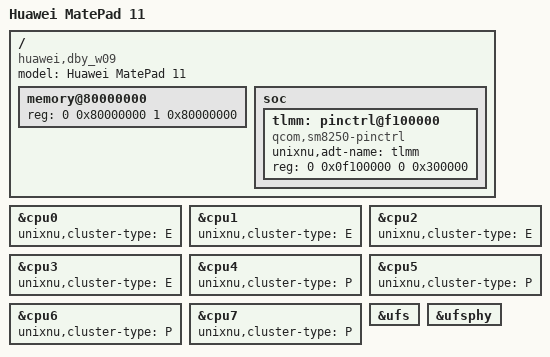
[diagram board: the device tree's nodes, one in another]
// SPDX-License-Identifier: BSD-3-Clause
// Huawei MatePad 11 (DBY-W09), Qualcomm SM8250 / kona, 8 Kryo 585 cores.
//
// Sources: the tablet's own Android device tree (kona-v2.1.dts plus the
// DBY/W09_VA overlay) for the DRAM base, size and CPU affinity numbering, and
// the shared SM8250 description from the pinned SoC repository for the
// controller registers. Board memory, enabled CPUs and enabled peripherals
// belong here; registers and interrupt geometry belong in sm8250.dtsi.

/dts-v1/;
/include/ "sm8250.dtsi"

/ {
    model = "Huawei MatePad 11";
    compatible = "huawei,dby_w09", "qcom,kona", "qcom,sm8250";

    memory@80000000 {
        device_type = "memory";
        // The tested unit has 6 GiB LPDDR5 in one contiguous bank starting at 0x80000000.
        // DRAM size is a variant on this model (6 or 8 GiB), so this is a per-unit value:
        // read it from the target unit and keep it equal to payload.dram_size in board.toml.
        // The ADT generator rejects any value that differs from payload.dram_size.
        reg = <0 0x80000000 1 0x80000000>;
    };
};

// All eight cores run: four Kryo 585 Silver (Cortex-A55) and four Gold (Cortex-A77).
&cpu0 { status = "okay"; };
&cpu1 { status = "okay"; };
&cpu2 { status = "okay"; };
&cpu3 { status = "okay"; };
&cpu4 { status = "okay"; };
&cpu5 { status = "okay"; };
&cpu6 { status = "okay"; };
&cpu7 { status = "okay"; };

/* Cluster topology, only valid together with native-smp-type-clusters.patch: without it the
 * topology parser maps a P core to cluster index 1 while MAX_CPU_CLUSTERS is 1 and writes past
 * the end of cluster_phys_to_logical on the stack (measured: the kernel dies before the console
 * comes up). The two must be enabled as one change. */
&cpu0 { unixnu,cluster-type = "E"; };
&cpu1 { unixnu,cluster-type = "E"; };
&cpu2 { unixnu,cluster-type = "E"; };
&cpu3 { unixnu,cluster-type = "E"; };
&cpu4 { unixnu,cluster-type = "P"; };
&cpu5 { unixnu,cluster-type = "P"; };
&cpu6 { unixnu,cluster-type = "P"; };
&cpu7 { unixnu,cluster-type = "P"; };

// Storage: the root volume is the UFS disk, so the host controller and its QMP
// PHY are the peripherals this board enables. sm8250.dtsi keeps both disabled
// until a board selects a storage component.
&ufs { status = "okay"; };
&ufsphy { status = "okay"; };

// Not enabled, with a reason recorded in porting.toml rather than silence:
//   gpu / gpu_smmu    - no catalog component provides the A650 (Adreno 650) path yet.
//   qupv3_id_0        - the touch panel's serial engine; the input component is not ported.

// Pin controller.
//
// Why it exists: 2026-10-31 the touch driver's census read all six GPIO_CFG words as 0x00000000
// (`PINS n=6 g039=00000000 g098=00000000 ...` on the diagnostics page and in the archived page
// slots), i.e. the window it maps carries no hardware. Only nodes that carry `unixnu,adt-name`
// are exported to the ADT (scripts/unixnu/devicetree.py:368), and the board described no pin
// controller at all, so it is the first thing to give the path a described window. UFS works
// because ufshc@1d84000 is described; this gives the pin path the same footing.
//
// Address: kona exposes three pin windows (0x0F100000 west, 0x0F500000 south, 0x0F900000 north).
// Only the west window is described here for now; if a pin the touch path needs (39/98/43/40/41/42)
// turns out to live in the south or north window, its node has to be added and the driver's linear
// `base + pin * 0x1000` model replaced by a per-window lookup.
//
// The QUPv3 wrapper (0x8C0000) and SE14 (0x880000) are deliberately NOT described yet: exporting a
// window below 16 MiB moves the arm-io base from 0x01000000 down to 0x00800000 and shifts every
// arm-io child offset (porting.toml records that base+offset still resolves, but every existing
// offset needs a re-check), and the serial engine must not be poked before its clock votes land.
/ {
    soc {
        tlmm: pinctrl@f100000 {
            compatible = "qcom,sm8250-pinctrl";
            unixnu,adt-name = "tlmm";
            reg = <0 0x0f100000 0 0x300000>;
        };
    };
};
